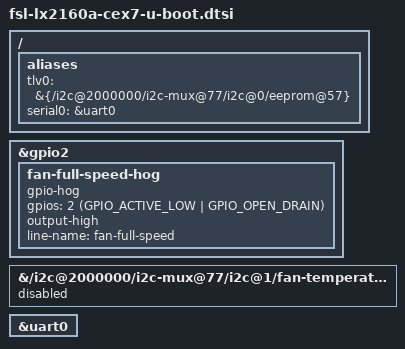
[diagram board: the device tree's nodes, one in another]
// SPDX-License-Identifier: GPL-2.0+

#include <dt-bindings/gpio/gpio.h>

/ {
	aliases {
		tlv0 = &{/i2c@2000000/i2c-mux@77/i2c@0/eeprom@57};
		serial0 = &uart0;
	};
};

&gpio2 {
	/*
	 * AMC6821 THERM signal uses open-drain logic and can be driven
	 * by either the host (force full-speed) or the chip
	 * (thermal warning). Firmware drives it low during reset.
	 *
	 * Force fan full-speed while bootloader is active.
	 * TODO: Add fan-controller driver.
	 */
	fan-full-speed-hog {
		gpio-hog;
		gpios = <2 (GPIO_ACTIVE_LOW | GPIO_OPEN_DRAIN)>;
		output-high;
		line-name = "fan-full-speed";
	};
};

&{/i2c@2000000/i2c-mux@77/i2c@1/fan-temperature-ctrlr@18} {
	/*u-boot does not currently have a driver for this fan-controller */
	status = "disabled";
};

&uart0 {
	status = "okay";
};
